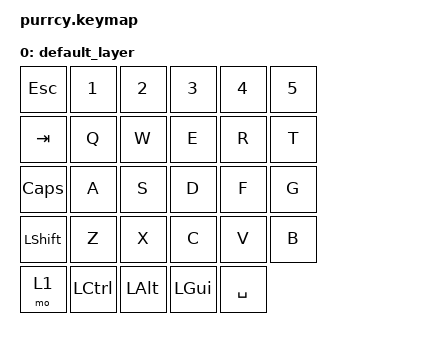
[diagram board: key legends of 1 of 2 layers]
#include <behaviors.dtsi>
#include <dt-bindings/zmk/keys.h>
#include <dt-bindings/zmk/bt.h>
#include <dt-bindings/zmk/outputs.h>

/ {
    keymap {
        compatible = "zmk,keymap";

        default_layer {
            bindings = <
                &kp ESC      &kp N1       &kp N2       &kp N3       &kp N4       &kp N5
                &kp TAB      &kp Q        &kp W        &kp E        &kp R        &kp T
                &kp CLCK     &kp A        &kp S        &kp D        &kp F        &kp G
                &kp LSHFT    &kp Z        &kp X        &kp C        &kp V        &kp B
                &mo 1        &kp LCTRL    &kp LALT     &kp LGUI     &kp SPACE
            >;
        };
        bt_layer {
            bindings = <
                &kp GRAVE    &kp F1       &kp F2       &kp F3       &kp F4       &kp F5
                &kp TAB      &bt BT_CLR   &bt BT_PRV   &bt BT_NXT   &kp R        &kp T
                &kp CLCK     &out OUT_BLE &kp S        &kp D        &kp F        &kp G
                &kp LSHFT    &kp Z        &kp X        &kp C        &kp V        &kp B
                &mo 1        &kp LCTRL    &kp LALT     &kp SPACE
            >;
        };
        
    };
};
